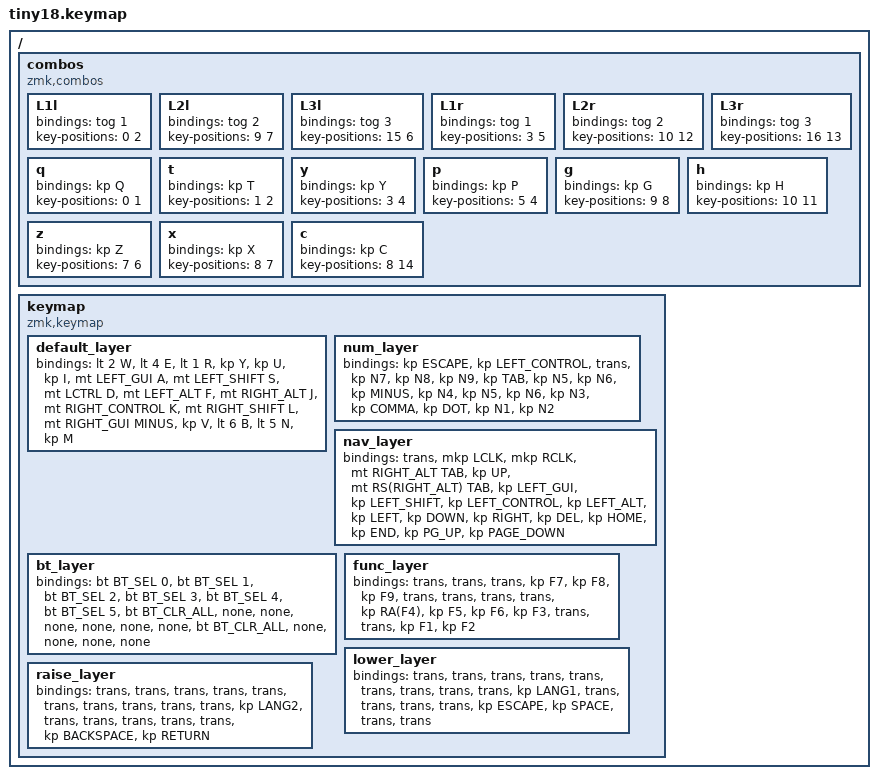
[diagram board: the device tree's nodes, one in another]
#include <input/processors.dtsi>
#include <dt-bindings/zmk/input_transform.h>
#include <zephyr/dt-bindings/input/input-event-codes.h>
#include <behaviors.dtsi>
#include <dt-bindings/zmk/bt.h>
#include <dt-bindings/zmk/keys.h>
#include <dt-bindings/zmk/pointing.h>

// OS設定を日本語キーボードのまま使用するための変換定義

#define JP_DQUOTE       AT                // "
#define JP_AMPERSAND    CARET             // &
#define JP_QUOTE        AMPERSAND         // '
#define JP_EQUAL        UNDER             // =
#define JP_CARET        EQUAL             // ^
#define JP_YEN          0x89              // ¥
#define JP_PLUS         COLON             // +
#define JP_TILDE        PLUS              // ~
#define JP_PIPE         LS(0x89)          // |
#define JP_AT           LEFT_BRACKET      // @
#define JP_COLON        SINGLE_QUOTE      // :
#define JP_ASTERISK     DOUBLE_QUOTES     // *
#define JP_BACKQUOTE    LEFT_BRACE        // `
#define JP_UNDERSCORE   LS(0x87)          // _
#define JP_LBRACKET     RIGHT_BRACKET     // [
#define JP_RBRACKET     BACKSLASH         // ]
#define JP_LPAREN       ASTERISK          // (
#define JP_RPAREN       LEFT_PARENTHESIS  // )
#define JP_LBRACE       RIGHT_BRACE       // {
#define JP_RBRACE       PIPE              // }
#define JP_KANA         LANGUAGE_1        // かな
#define JP_EISU         LANGUAGE_2        // 英数
#define JP_HANZEN       GRAVE             // 半角/全角

/ {
    combos {
        compatible = "zmk,combos";

        /***** key-positions *****
   0  1  2     3  4  5
6  7  8  9    10 11 12 13
     14 15    16 17
*************************/

        L1l {
            bindings = <&tog 1>;
            key-positions = <0 2>;
        };

        L2l {
            bindings = <&tog 2>;
            key-positions = <9 7>;
        };

        L3l {
            bindings = <&tog 3>;
            key-positions = <15 6>;
        };

        L1r {
            bindings = <&tog 1>;
            key-positions = <3 5>;
        };

        L2r {
            bindings = <&tog 2>;
            key-positions = <10 12>;
        };

        L3r {
            bindings = <&tog 3>;
            key-positions = <16 13>;
        };

        q {
            bindings = <&kp Q>;
            key-positions = <0 1>;
        };

        t {
            bindings = <&kp T>;
            key-positions = <1 2>;
        };

        y {
            bindings = <&kp Y>;
            key-positions = <3 4>;
        };

        p {
            bindings = <&kp P>;
            key-positions = <5 4>;
        };

        g {
            bindings = <&kp G>;
            key-positions = <9 8>;
        };

        h {
            bindings = <&kp H>;
            key-positions = <10 11>;
        };

        z {
            bindings = <&kp Z>;
            key-positions = <7 6>;
        };

        x {
            bindings = <&kp X>;
            key-positions = <8 7>;
        };

        c {
            bindings = <&kp C>;
            key-positions = <8 14>;
        };
    };

    keymap {
        compatible = "zmk,keymap";

        default_layer: default_layer {
            bindings = <
&lt 2 W  &lt 4 E  &lt 1 R  &kp Y  &kp U  &kp I  &mt LEFT_GUI A  &mt LEFT_SHIFT S  &mt LCTRL D  &mt LEFT_ALT F  &mt RIGHT_ALT J  &mt RIGHT_CONTROL K  &mt RIGHT_SHIFT L  &mt RIGHT_GUI MINUS  &kp V  &lt 6 B  &lt 5 N  &kp M
            >;
        };

        num_layer: num_layer {
            bindings = <
&kp ESCAPE  &kp LEFT_CONTROL  &trans  &kp N7  &kp N8  &kp N9  &kp TAB  &kp N5  &kp N6  &kp MINUS  &kp N4  &kp N5  &kp N6  &kp N3  &kp COMMA  &kp DOT  &kp N1  &kp N2
            >;
        };

        nav_layer: nav_layer {
            bindings = <
&trans  &mkp LCLK  &mkp RCLK  &mt RIGHT_ALT TAB  &kp UP  &mt RS(RIGHT_ALT) TAB  &kp LEFT_GUI  &kp LEFT_SHIFT  &kp LEFT_CONTROL  &kp LEFT_ALT  &kp LEFT  &kp DOWN  &kp RIGHT  &kp DEL  &kp HOME  &kp END  &kp PG_UP  &kp PAGE_DOWN
            >;
        };

        bt_layer: bt_layer {
            bindings = <
&bt BT_SEL 0  &bt BT_SEL 1  &bt BT_SEL 2  &bt BT_SEL 3  &bt BT_SEL 4  &bt BT_SEL 5  &bt BT_CLR_ALL  &none  &none  &none  &none  &none  &none  &bt BT_CLR_ALL  &none  &none  &none  &none
            >;
        };

        func_layer {
            bindings = <
&trans  &trans  &trans  &kp F7  &kp F8  &kp F9  &trans  &trans  &trans  &trans  &kp RA(F4)  &kp F5  &kp F6  &kp F3  &trans  &trans  &kp F1  &kp F2
            >;
        };

        lower_layer {
            bindings = <
&trans  &trans  &trans  &trans  &trans  &trans  &trans  &trans  &trans  &kp LANG1  &trans  &trans  &trans  &trans  &kp ESCAPE  &kp SPACE  &trans  &trans
            >;
        };

        raise_layer {
            bindings = <
&trans  &trans  &trans  &trans  &trans  &trans  &trans  &trans  &trans  &trans  &kp LANG2  &trans  &trans  &trans  &trans  &trans  &kp BACKSPACE  &kp RETURN
            >;
        };
    };
};
